# ioam3358 register map
Registers are 32-bit, access not given, no defined reset value unless marked. A register's access mark holds for its fields unless they carry their own. Addresses are absolute; registers are grouped by the start of their names; [hi:lo] are bit positions; {n}, {i} and the like mark numbered series.

## PRUSS
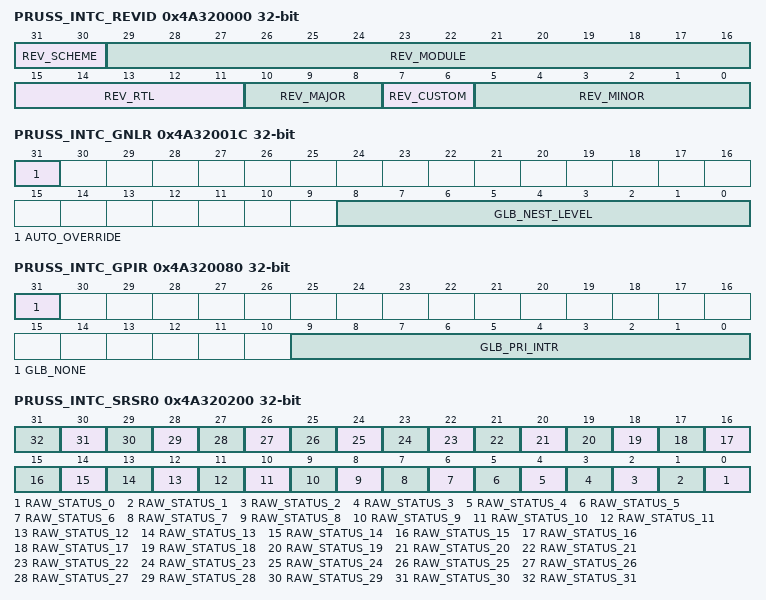
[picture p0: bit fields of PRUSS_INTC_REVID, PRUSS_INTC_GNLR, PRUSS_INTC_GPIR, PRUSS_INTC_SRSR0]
0x4A320000 PRUSS_INTC_REVID
  [31:30] REV_SCHEME, [29:16] REV_MODULE, [15:11] REV_RTL, [10:8] REV_MAJOR, [7:6] REV_CUSTOM, [5:0] REV_MINOR
0x4A320004 PRUSS_INTC_CR
  [3:2] NEST_MODE
0x4A320010 PRUSS_INTC_GER
  [0] ENABLE_HINT_ANY
0x4A32001C PRUSS_INTC_GNLR
  [31] AUTO_OVERRIDE, [8:0] GLB_NEST_LEVEL
0x4A320020 PRUSS_INTC_SISR
0x4A320024 PRUSS_INTC_SICR
0x4A320028 PRUSS_INTC_EISR
0x4A32002C PRUSS_INTC_EICR
0x4A320034 PRUSS_INTC_HIEISR
0x4A320038 PRUSS_INTC_HIDISR
0x4A320080 PRUSS_INTC_GPIR
  [31] GLB_NONE, [9:0] GLB_PRI_INTR
0x4A320200 PRUSS_INTC_SRSR0
  [n] RAW_STATUS_{n} (n=0..31)
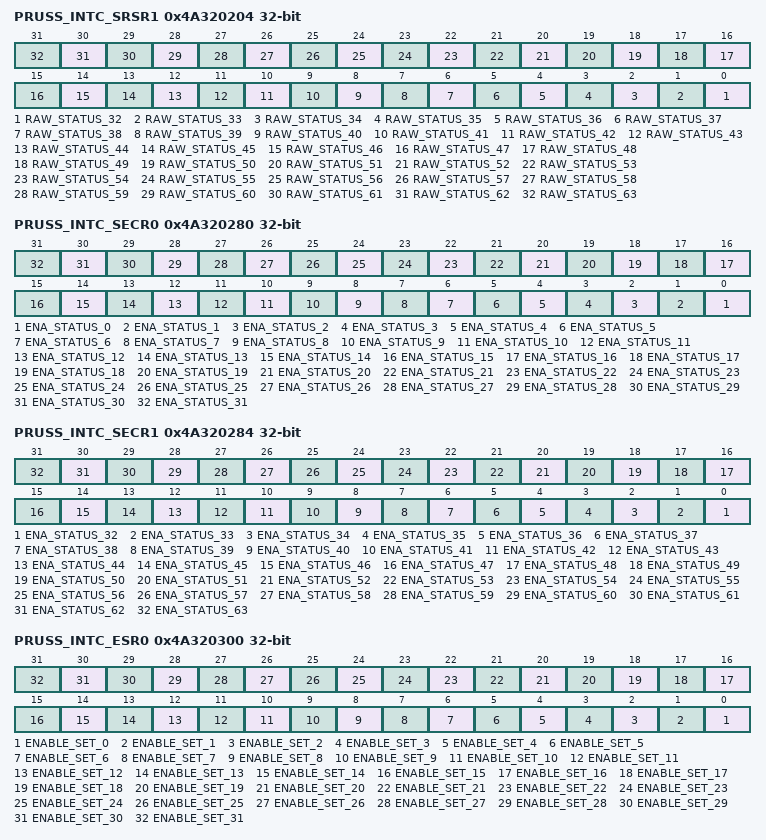
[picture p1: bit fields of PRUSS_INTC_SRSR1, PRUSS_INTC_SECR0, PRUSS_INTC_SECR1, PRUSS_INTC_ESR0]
0x4A320204 PRUSS_INTC_SRSR1
  [n-32] RAW_STATUS_{n} (n=32..63)
0x4A320280 PRUSS_INTC_SECR0
  [n] ENA_STATUS_{n} (n=0..31)
0x4A320284 PRUSS_INTC_SECR1
  [n-32] ENA_STATUS_{n} (n=32..63)
0x4A320300 PRUSS_INTC_ESR0
  [n] ENABLE_SET_{n} (n=0..31)
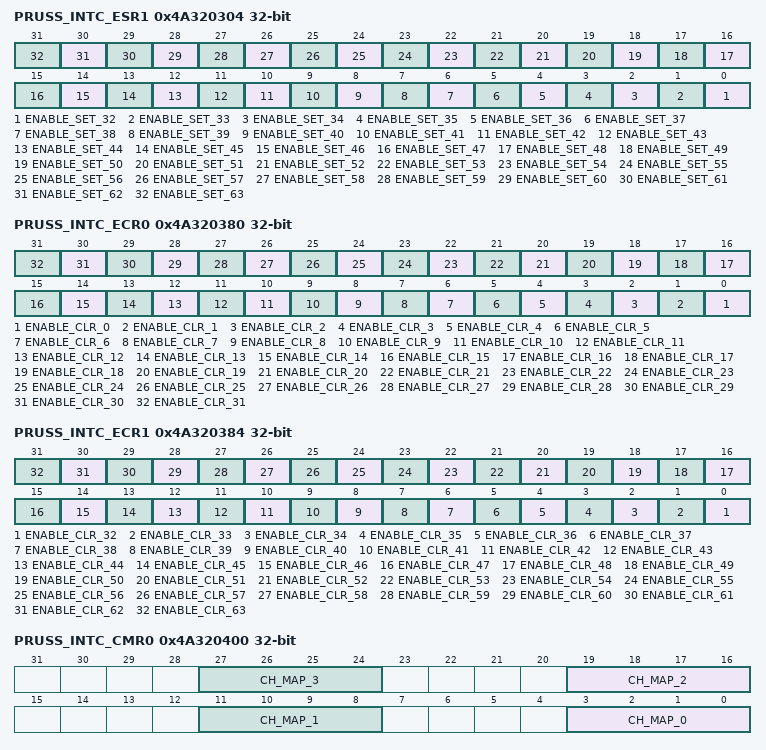
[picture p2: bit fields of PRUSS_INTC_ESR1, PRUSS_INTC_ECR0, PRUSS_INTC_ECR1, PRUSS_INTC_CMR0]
0x4A320304 PRUSS_INTC_ESR1
  [n-32] ENABLE_SET_{n} (n=32..63)
0x4A320380 PRUSS_INTC_ECR0
  [n] ENABLE_CLR_{n} (n=0..31)
0x4A320384 PRUSS_INTC_ECR1
  [n-32] ENABLE_CLR_{n} (n=32..63)
0x4A320400 PRUSS_INTC_CMR0
  [8n+3:8n] CH_MAP_{n} (n=0..3)
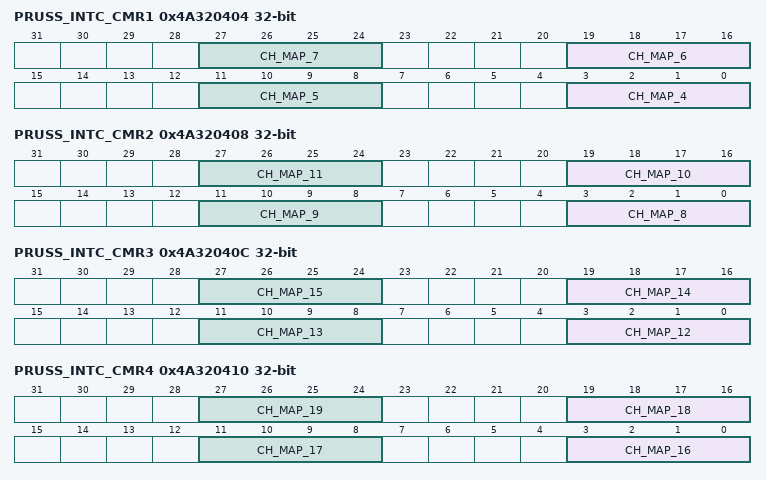
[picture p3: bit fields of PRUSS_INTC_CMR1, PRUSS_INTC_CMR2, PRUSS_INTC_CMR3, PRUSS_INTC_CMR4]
0x4A320404 PRUSS_INTC_CMR1
  [8n-29:8n-32] CH_MAP_{n} (n=4..7)
0x4A320408 PRUSS_INTC_CMR2
  [8n-61:8n-64] CH_MAP_{n} (n=8..11)
0x4A32040C PRUSS_INTC_CMR3
  [8n-93:8n-96] CH_MAP_{n} (n=12..15)
0x4A320410 PRUSS_INTC_CMR4
  [8n-125:8n-128] CH_MAP_{n} (n=16..19)
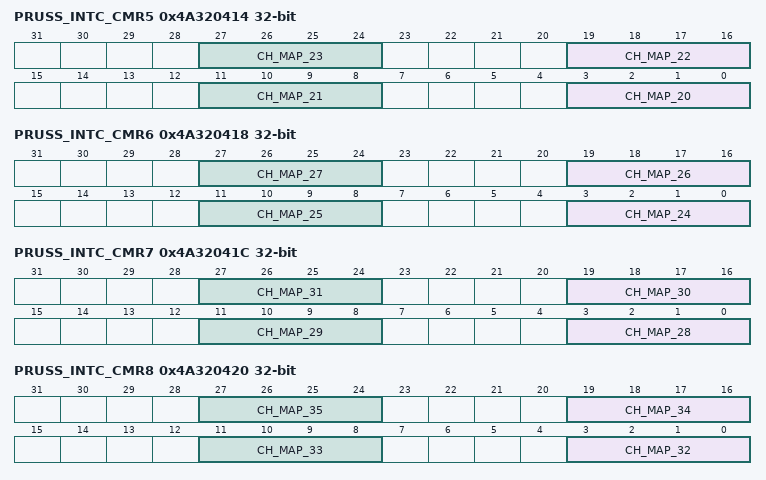
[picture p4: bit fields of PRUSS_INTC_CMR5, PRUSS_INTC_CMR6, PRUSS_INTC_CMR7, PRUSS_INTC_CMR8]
0x4A320414 PRUSS_INTC_CMR5
  [8n-157:8n-160] CH_MAP_{n} (n=20..23)
0x4A320418 PRUSS_INTC_CMR6
  [8n-189:8n-192] CH_MAP_{n} (n=24..27)
0x4A32041C PRUSS_INTC_CMR7
  [8n-221:8n-224] CH_MAP_{n} (n=28..31)
0x4A320420 PRUSS_INTC_CMR8
  [8n-253:8n-256] CH_MAP_{n} (n=32..35)
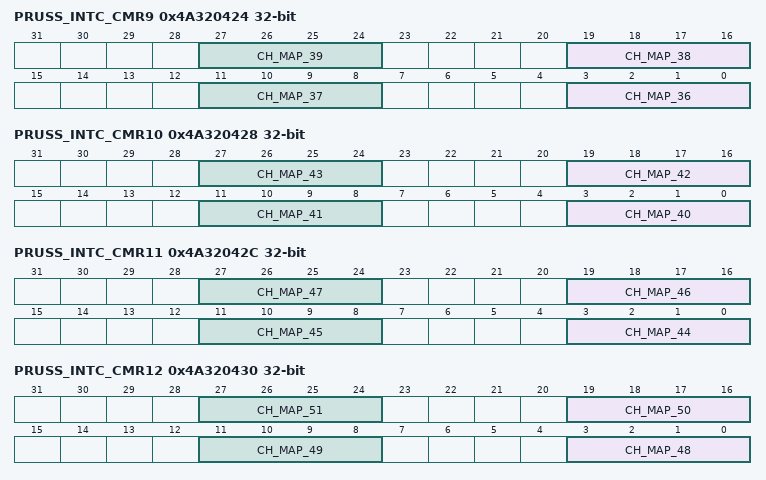
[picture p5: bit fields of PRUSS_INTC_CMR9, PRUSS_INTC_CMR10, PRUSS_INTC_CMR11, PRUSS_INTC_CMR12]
0x4A320424 PRUSS_INTC_CMR9
  [8n-285:8n-288] CH_MAP_{n} (n=36..39)
0x4A320428 PRUSS_INTC_CMR10
  [8n-317:8n-320] CH_MAP_{n} (n=40..43)
0x4A32042C PRUSS_INTC_CMR11
  [8n-349:8n-352] CH_MAP_{n} (n=44..47)
0x4A320430 PRUSS_INTC_CMR12
  [8n-381:8n-384] CH_MAP_{n} (n=48..51)
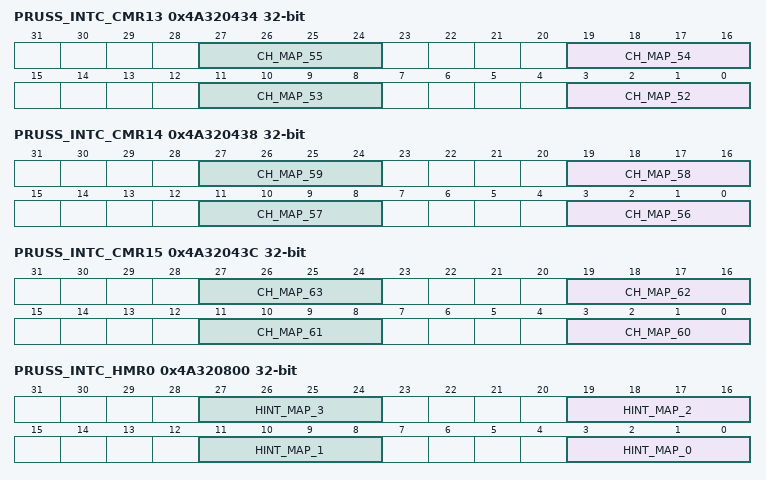
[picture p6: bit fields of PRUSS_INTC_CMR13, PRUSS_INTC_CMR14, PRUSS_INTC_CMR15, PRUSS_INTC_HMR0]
0x4A320434 PRUSS_INTC_CMR13
  [8n-413:8n-416] CH_MAP_{n} (n=52..55)
0x4A320438 PRUSS_INTC_CMR14
  [8n-445:8n-448] CH_MAP_{n} (n=56..59)
0x4A32043C PRUSS_INTC_CMR15
  [8n-477:8n-480] CH_MAP_{n} (n=60..63)
0x4A320800 PRUSS_INTC_HMR0
  [8n+3:8n] HINT_MAP_{n} (n=0..3)
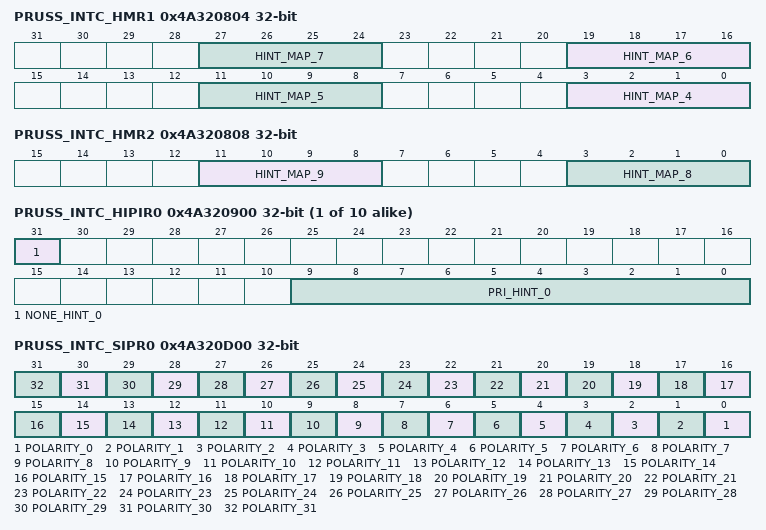
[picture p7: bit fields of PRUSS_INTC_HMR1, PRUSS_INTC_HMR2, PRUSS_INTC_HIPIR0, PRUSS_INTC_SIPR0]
0x4A320804 PRUSS_INTC_HMR1
  [8n-29:8n-32] HINT_MAP_{n} (n=4..7)
0x4A320808 PRUSS_INTC_HMR2
  [11:8] HINT_MAP_9, [3:0] HINT_MAP_8
{0x4A320900+4i} PRUSS_INTC_HIPIR{i} (i=0..9)
  [31] NONE_HINT_{i}, [9:0] PRI_HINT_{i}
0x4A320D00 PRUSS_INTC_SIPR0
  [n] POLARITY_{n} (n=0..31)
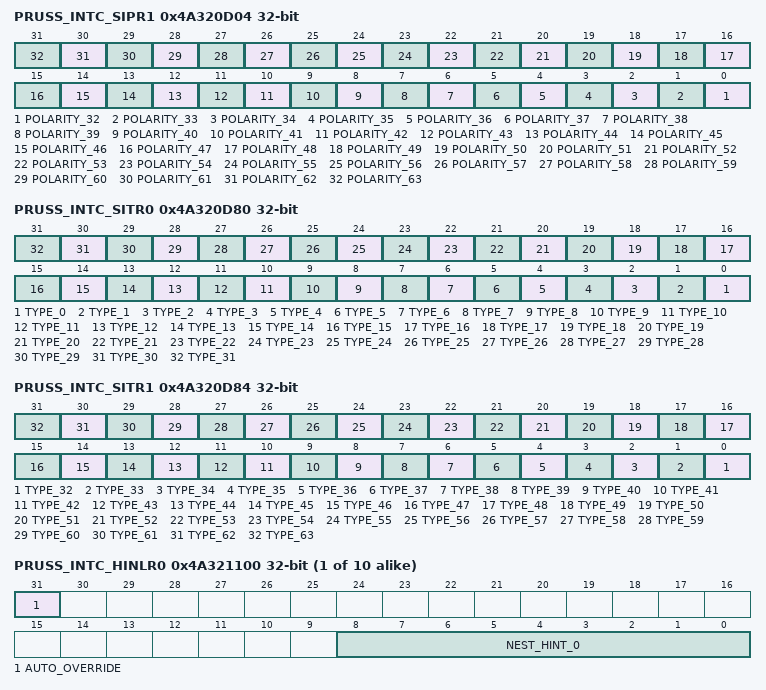
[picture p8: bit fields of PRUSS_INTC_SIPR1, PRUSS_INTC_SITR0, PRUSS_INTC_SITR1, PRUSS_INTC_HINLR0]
0x4A320D04 PRUSS_INTC_SIPR1
  [n-32] POLARITY_{n} (n=32..63)
0x4A320D80 PRUSS_INTC_SITR0
  [n] TYPE_{n} (n=0..31)
0x4A320D84 PRUSS_INTC_SITR1
  [n-32] TYPE_{n} (n=32..63)
{0x4A321100+4i} PRUSS_INTC_HINLR{i} (i=0..9)
  [31] AUTO_OVERRIDE, [8:0] NEST_HINT_{i}
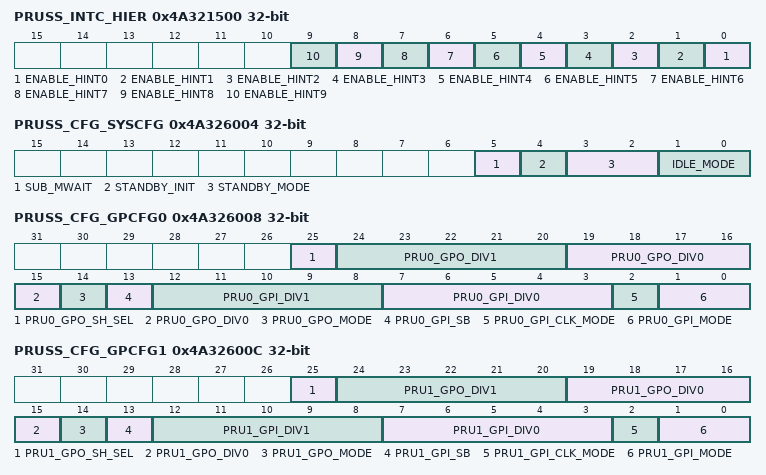
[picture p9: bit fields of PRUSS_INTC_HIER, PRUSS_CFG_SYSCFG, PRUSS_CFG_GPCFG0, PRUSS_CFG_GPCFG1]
0x4A321500 PRUSS_INTC_HIER
  [n] ENABLE_HINT{n} (n=0..9)
0x4A326000 PRUSS_CFG_REVID
0x4A326004 PRUSS_CFG_SYSCFG
  [5] SUB_MWAIT, [4] STANDBY_INIT, [3:2] STANDBY_MODE, [1:0] IDLE_MODE
0x4A326008 PRUSS_CFG_GPCFG0
  [25] PRU0_GPO_SH_SEL, [24:20] PRU0_GPO_DIV1, [19:15] PRU0_GPO_DIV0, [14] PRU0_GPO_MODE, [13] PRU0_GPI_SB, [12:8] PRU0_GPI_DIV1, [7:3] PRU0_GPI_DIV0, [2] PRU0_GPI_CLK_MODE, [1:0] PRU0_GPI_MODE
0x4A32600C PRUSS_CFG_GPCFG1
  [25] PRU1_GPO_SH_SEL, [24:20] PRU1_GPO_DIV1, [19:15] PRU1_GPO_DIV0, [14] PRU1_GPO_MODE, [13] PRU1_GPI_SB, [12:8] PRU1_GPI_DIV1, [7:3] PRU1_GPI_DIV0, [2] PRU1_GPI_CLK_MODE, [1:0] PRU1_GPI_MODE
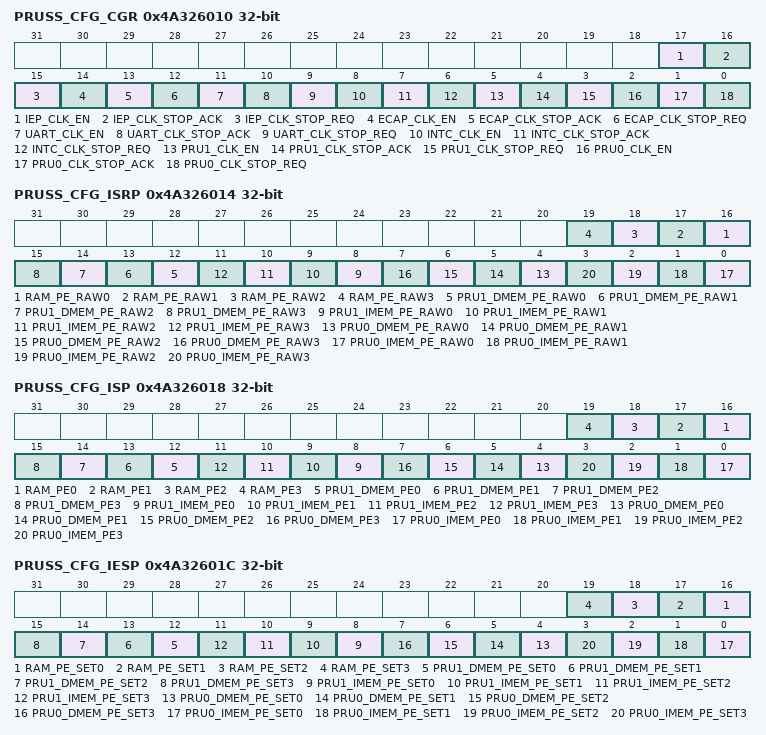
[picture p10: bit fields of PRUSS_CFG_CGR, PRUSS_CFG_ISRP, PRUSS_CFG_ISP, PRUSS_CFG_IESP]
0x4A326010 PRUSS_CFG_CGR
  [17] IEP_CLK_EN, [16] IEP_CLK_STOP_ACK, [15] IEP_CLK_STOP_REQ, [14] ECAP_CLK_EN, [13] ECAP_CLK_STOP_ACK, [12] ECAP_CLK_STOP_REQ, [11] UART_CLK_EN, [10] UART_CLK_STOP_ACK, [9] UART_CLK_STOP_REQ, [8] INTC_CLK_EN, [7] INTC_CLK_STOP_ACK, [6] INTC_CLK_STOP_REQ, [5] PRU1_CLK_EN, [4] PRU1_CLK_STOP_ACK, [3] PRU1_CLK_STOP_REQ, [2] PRU0_CLK_EN, [1] PRU0_CLK_STOP_ACK, [0] PRU0_CLK_STOP_REQ
0x4A326014 PRUSS_CFG_ISRP
  [n+16] RAM_PE_RAW{n} (n=0..3), [n+12] PRU1_DMEM_PE_RAW{n} (n=0..3), [n+8] PRU1_IMEM_PE_RAW{n} (n=0..3), [n+4] PRU0_DMEM_PE_RAW{n} (n=0..3), [n] PRU0_IMEM_PE_RAW{n} (n=0..3)
0x4A326018 PRUSS_CFG_ISP
  [n+16] RAM_PE{n} (n=0..3), [n+12] PRU1_DMEM_PE{n} (n=0..3), [n+8] PRU1_IMEM_PE{n} (n=0..3), [n+4] PRU0_DMEM_PE{n} (n=0..3), [n] PRU0_IMEM_PE{n} (n=0..3)
0x4A32601C PRUSS_CFG_IESP
  [n+16] RAM_PE_SET{n} (n=0..3), [n+12] PRU1_DMEM_PE_SET{n} (n=0..3), [n+8] PRU1_IMEM_PE_SET{n} (n=0..3), [n+4] PRU0_DMEM_PE_SET{n} (n=0..3), [n] PRU0_IMEM_PE_SET{n} (n=0..3)
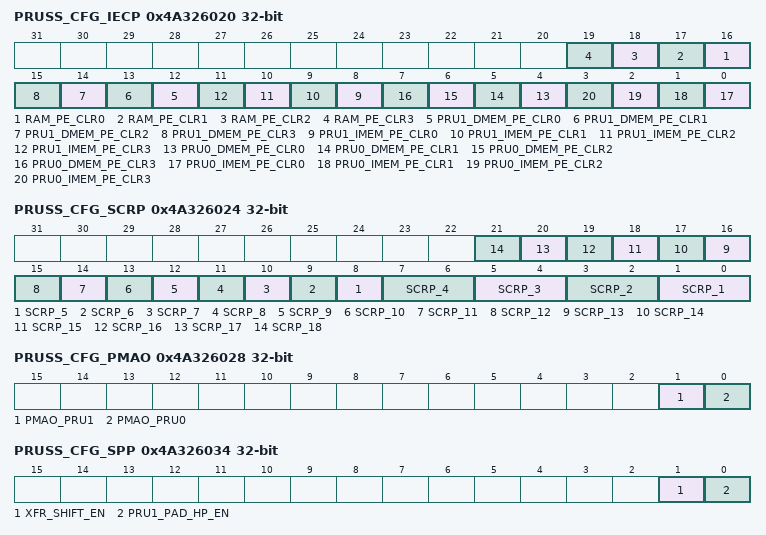
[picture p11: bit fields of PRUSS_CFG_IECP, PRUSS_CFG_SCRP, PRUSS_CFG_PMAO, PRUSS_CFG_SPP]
0x4A326020 PRUSS_CFG_IECP
  [n+16] RAM_PE_CLR{n} (n=0..3), [n+12] PRU1_DMEM_PE_CLR{n} (n=0..3), [n+8] PRU1_IMEM_PE_CLR{n} (n=0..3), [n+4] PRU0_DMEM_PE_CLR{n} (n=0..3), [n] PRU0_IMEM_PE_CLR{n} (n=0..3)
0x4A326024 PRUSS_CFG_SCRP
  [n+3] SCRP_{n} (n=5..18), [2n-1:2n-2] SCRP_{n} (n=1..4)
0x4A326028 PRUSS_CFG_PMAO
  [1] PMAO_PRU1, [0] PMAO_PRU0
0x4A32602C PRUSS_CFG_MII_RT
  [0] MII_RT_EVENT_EN
0x4A326030 PRUSS_CFG_IEPCLK
  [0] OCP_EN
0x4A326034 PRUSS_CFG_SPP
  [1] XFR_SHIFT_EN, [0] PRU1_PAD_HP_EN
0x4A326040 PRUSS_CFG_PIN_MX
  [7:0] PIN_MUX_SEL
0x4A328000 PRUSS_UART0_RBR
  [7:0] DATA
0x4A328000 PRUSS_UART0_THR
  [7:0] DATA
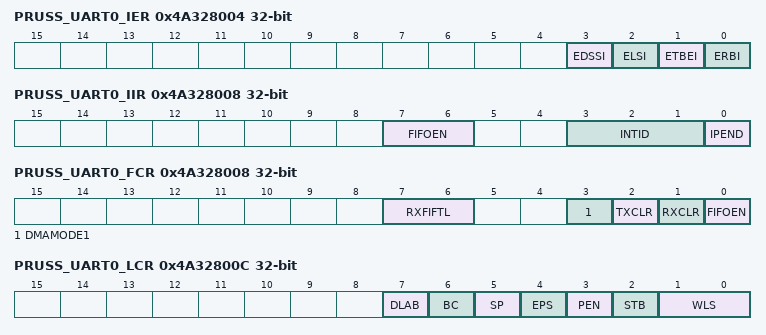
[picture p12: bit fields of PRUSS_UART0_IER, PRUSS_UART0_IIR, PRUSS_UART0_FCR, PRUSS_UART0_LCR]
0x4A328004 PRUSS_UART0_IER
  [3] EDSSI, [2] ELSI, [1] ETBEI, [0] ERBI
0x4A328008 PRUSS_UART0_IIR
  [7:6] FIFOEN, [3:1] INTID, [0] IPEND
0x4A328008 PRUSS_UART0_FCR
  [7:6] RXFIFTL, [3] DMAMODE1, [2] TXCLR, [1] RXCLR, [0] FIFOEN
0x4A32800C PRUSS_UART0_LCR
  [7] DLAB, [6] BC, [5] SP, [4] EPS, [3] PEN, [2] STB, [1:0] WLS
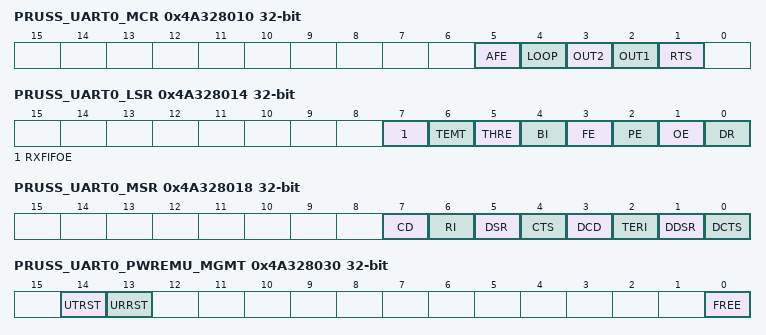
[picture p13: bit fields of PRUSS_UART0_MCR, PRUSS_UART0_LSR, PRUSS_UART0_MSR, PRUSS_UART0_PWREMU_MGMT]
0x4A328010 PRUSS_UART0_MCR
  [5] AFE, [4] LOOP, [3] OUT2, [2] OUT1, [1] RTS
0x4A328014 PRUSS_UART0_LSR
  [7] RXFIFOE, [6] TEMT, [5] THRE, [4] BI, [3] FE, [2] PE, [1] OE, [0] DR
0x4A328018 PRUSS_UART0_MSR
  [7] CD, [6] RI, [5] DSR, [4] CTS, [3] DCD, [2] TERI, [1] DDSR, [0] DCTS
0x4A32801C PRUSS_UART0_SCR
  [7:0] SCR
0x4A328020 PRUSS_UART0_DLL
  [7:0] DLL
0x4A328024 PRUSS_UART0_DLH
  [7:0] DLH
0x4A328028 PRUSS_UART0_REVID1
0x4A32802C PRUSS_UART0_REVID2
  [7:0] REVID2
0x4A328030 PRUSS_UART0_PWREMU_MGMT
  [14] UTRST, [13] URRST, [0] FREE
0x4A328034 PRUSS_UART0_MDR
  [0] OSM_SEL
0x4A330000 PRUSS_ECAP0_TSCTR
0x4A330004 PRUSS_ECAP0_CTRPHS
{0x4A330004+4i} PRUSS_ECAP0_CAP{i} (i=1..4)
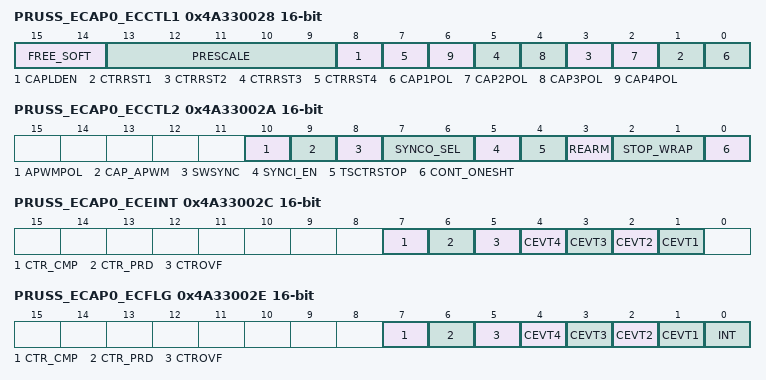
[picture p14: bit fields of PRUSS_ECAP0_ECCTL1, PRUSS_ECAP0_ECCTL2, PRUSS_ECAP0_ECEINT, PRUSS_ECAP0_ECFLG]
0x4A330028 PRUSS_ECAP0_ECCTL1 16-bit
  [15:14] FREE_SOFT, [13:9] PRESCALE, [8] CAPLDEN, [2n-1] CTRRST{n} (n=1..4), [2n-2] CAP{n}POL (n=1..4)
0x4A33002A PRUSS_ECAP0_ECCTL2 16-bit
  [10] APWMPOL, [9] CAP_APWM, [8] SWSYNC, [7:6] SYNCO_SEL, [5] SYNCI_EN, [4] TSCTRSTOP, [3] REARM, [2:1] STOP_WRAP, [0] CONT_ONESHT
0x4A33002C PRUSS_ECAP0_ECEINT 16-bit
  [7] CTR_CMP, [6] CTR_PRD, [5] CTROVF, [n] CEVT{n} (n=1..4)
0x4A33002E PRUSS_ECAP0_ECFLG 16-bit
  [7] CTR_CMP, [6] CTR_PRD, [5] CTROVF, [n] CEVT{n} (n=1..4), [0] INT
0x4A330030 PRUSS_ECAP0_ECCLR 16-bit
  [7] CTR_CMP, [6] CTR_PRD, [5] CTROVF, [n] CEVT{n} (n=1..4), [0] INT
0x4A330032 PRUSS_ECAP0_ECFRC 16-bit
  [7] CTR_CMP, [6] CTR_PRD, [5] CTROVF, [n] CEVT{n} (n=1..4)
0x4A33005C PRUSS_ECAP0_REVID
